# AT32UC3B0128 device description
Architecture: AVR32_UC3; Family: AVR UC3
Registers are 32-bit, read-write, reset 0x0 unless marked. A register's access mark holds for its fields unless they carry their own. Offsets are from the block's base; [hi:lo] are bit positions; {n}, {i} and the like mark numbered series.

## RTC — Real Time Counter
Instances: RTC 0xffff0d00
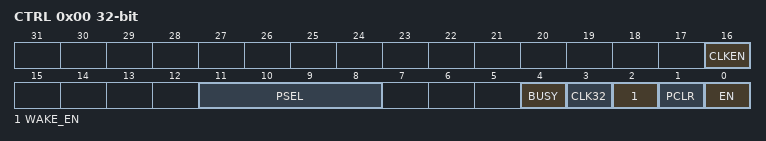
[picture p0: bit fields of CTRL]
0x00 CTRL — Real Time Counter Control
  [16] CLKEN — Clock enable
  [11:8] PSEL — Prescale Select
  [4] BUSY — Busy bit
  [3] CLK32 — Select 32KHz oscillator instead of RC Oscillator
  [2] WAKE_EN — Wake enable
  [1] PCLR — Prescaler Clear (strobe)
  [0] EN — Enable
0x04 VAL — RTC Value
0x08 TOP — RTC Top Value
  [31:0] VAL
0x10 IER wo — RTC Interrupt Enable Register
  [0] TOPI — TOP Interrupt
0x14 IDR wo — RTC Interrupt Disable Register
  [0] TOPI — TOP Interrupt
0x18 IMR ro — RTC Interrupt Mask Register
  [0] TOPI — TOP Interrupt
0x1C ISR ro — RTC Interrupt Status Register
  [0] TOPI — TOP Interrupt
0x20 ICR wo — RTC Interrupt Clear Register
  [0] TOPI — TOP Interrupt

## SPI — Serial Peripheral Interface
Instances: SPI0 0xffff2400
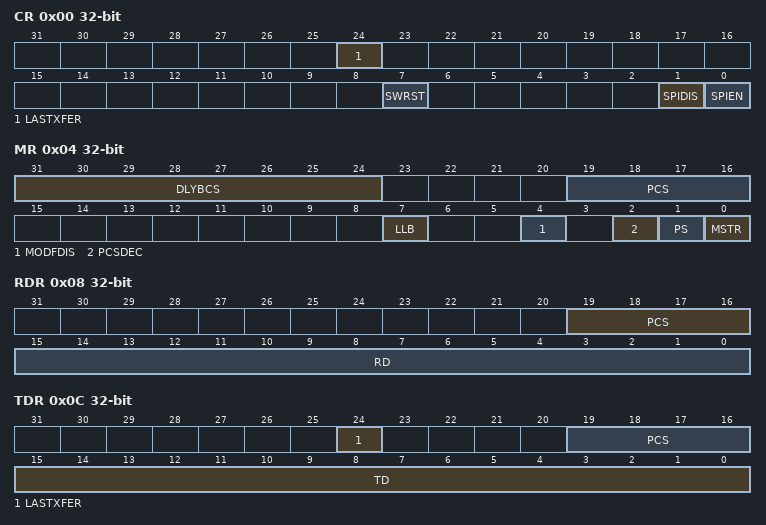
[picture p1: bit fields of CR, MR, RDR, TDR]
0x00 CR wo — Control Register
  [24] LASTXFER — Last Transfer
  [7] SWRST — SPI Software Reset
  [1] SPIDIS — SPI Disable
  [0] SPIEN — SPI Enable
0x04 MR — Mode Register
  [31:24] DLYBCS — Delay Between Chip Selects
  [19:16] PCS — Peripheral Chip Select
  [7] LLB — Local Loopback Enable
  [4] MODFDIS — Mode Fault Detection
  [2] PCSDEC — Chip Select Decode
  [1] PS — Peripheral Select
  [0] MSTR — Master/Slave Mode
0x08 RDR ro — Receive Data Register
  [19:16] PCS — Peripheral Chip Select
  [15:0] RD — Receive Data
0x0C TDR wo — Transmit Data Register
  [24] LASTXFER — Last Transfer
  [19:16] PCS — Peripheral Chip Select
  [15:0] TD — Transmit Data
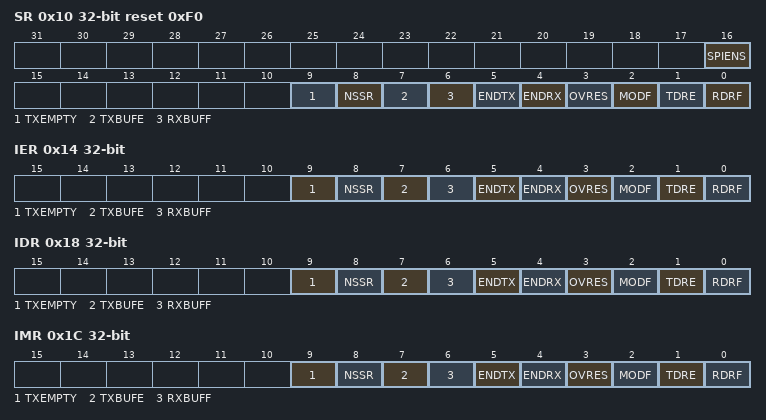
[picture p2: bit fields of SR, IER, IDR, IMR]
0x10 SR ro reset 0xF0 — Status Register
  [16] SPIENS — SPI Enable Status
  [9] TXEMPTY — Transmission Registers Empty
  [8] NSSR — NSS Rising
  [7] TXBUFE — TX Buffer Empty
  [6] RXBUFF — RX Buffer Full
  [5] ENDTX — End of TX buffer
  [4] ENDRX — End of RX buffer
  [3] OVRES — Overrun Error Status
  [2] MODF — Mode Fault Error
  [1] TDRE — Transmit Data Register Empty
  [0] RDRF — Receive Data Register Full
0x14 IER wo — Interrupt Enable Register
  [9] TXEMPTY — Transmission Registers Empty Enable
  [8] NSSR — NSS Rising Interrupt Enable
  [7] TXBUFE — Transmit Buffer Empty Interrupt Enable
  [6] RXBUFF — Receive Buffer Full Interrupt Enable
  [5] ENDTX — End of Transmit Buffer Interrupt Enable
  [4] ENDRX — End of Receive Buffer Interrupt Enable
  [3] OVRES — Overrun Error Interrupt Enable
  [2] MODF — Mode Fault Error Interrupt Enable
  [1] TDRE — Transmit Data Register Empty Interrupt Enable
  [0] RDRF — Receive Data Register Full Interrupt Enable
0x18 IDR wo — Interrupt Disable Register
  [9] TXEMPTY — Transmission Registers Empty Disable
  [8] NSSR — NSS Rising Interrupt Disable
  [7] TXBUFE — Transmit Buffer Empty Interrupt Disable
  [6] RXBUFF — Receive Buffer Full Interrupt Disable
  [5] ENDTX — End of Transmit Buffer Interrupt Disable
  [4] ENDRX — End of Receive Buffer Interrupt Disable
  [3] OVRES — Overrun Error Interrupt Disable
  [2] MODF — Mode Fault Error Interrupt Disable
  [1] TDRE — Transmit Data Register Empty Interrupt Disable
  [0] RDRF — Receive Data Register Full Interrupt Disable
0x1C IMR ro — Interrupt Mask Register
  [9] TXEMPTY — Transmission Registers Empty Mask
  [8] NSSR — NSS Rising Interrupt Mask
  [7] TXBUFE — Transmit Buffer Empty Interrupt Mask
  [6] RXBUFF — Receive Buffer Full Interrupt Mask
  [5] ENDTX — End of Transmit Buffer Interrupt Mask
  [4] ENDRX — End of Receive Buffer Interrupt Mask
  [3] OVRES — Overrun Error Interrupt Mask
  [2] MODF — Mode Fault Error Interrupt Mask
  [1] TDRE — Transmit Data Register Empty Interrupt Mask
  [0] RDRF — Receive Data Register Full Interrupt Mask
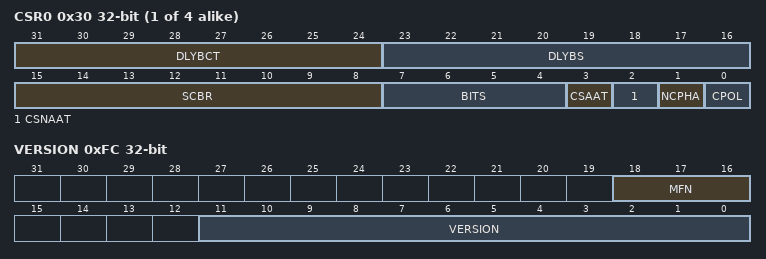
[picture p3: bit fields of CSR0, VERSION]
{0x30+4i} CSR{i} (i=0..3) — Chip Select Register {i}
  [31:24] DLYBCT — Delay Between Consecutive Transfers
  [23:16] DLYBS — Delay Before SPCK
  [15:8] SCBR — Serial Clock Baud Rate
  [7:4] BITS — Bits Per Transfer
    {v}={v+8}_BPT (v=0..8)
  [3] CSAAT — Chip Select Active After Transfer
  [2] CSNAAT — Chip Select Not Active After Transfer
  [1] NCPHA — Clock Phase
  [0] CPOL — Clock Polarity
0xFC VERSION ro
  [18:16] MFN, [11:0] VERSION
